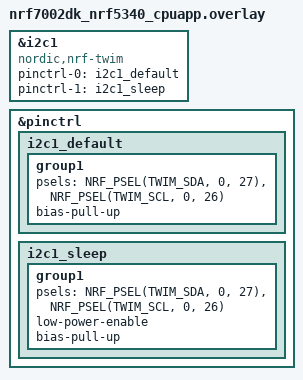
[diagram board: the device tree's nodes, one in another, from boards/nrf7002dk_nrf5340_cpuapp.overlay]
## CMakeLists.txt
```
cmake_minimum_required(VERSION 3.20.0)
find_package(Zephyr REQUIRED HINTS $ENV{ZEPHYR_BASE})
project(i2c_mmc5983ma_test)

target_sources(app PRIVATE src/main.c)
```

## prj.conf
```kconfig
# 基础功能
CONFIG_MAIN_STACK_SIZE=2048
CONFIG_SYSTEM_WORKQUEUE_STACK_SIZE=2048
CONFIG_HEAP_MEM_POOL_SIZE=1024

# I2C 支持
CONFIG_I2C=y

# 打印与日志系统
CONFIG_PRINTK=y
CONFIG_CONSOLE=y
CONFIG_UART_CONSOLE=y
CONFIG_SERIAL=y
CONFIG_LOG=y
CONFIG_LOG_DEFAULT_LEVEL=3
CONFIG_LOG_BACKEND_UART=y
CONFIG_STDOUT_CONSOLE=y


CONFIG_CBPRINTF_FP_SUPPORT=y
CONFIG_LOG=y
```

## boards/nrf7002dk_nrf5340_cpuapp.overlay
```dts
&i2c1 {
    compatible = "nordic,nrf-twim";
    status = "okay";
    pinctrl-0 = <&i2c1_default>;
    pinctrl-1 = <&i2c1_sleep>;
    pinctrl-names = "default", "sleep";
};

&pinctrl {
    i2c1_default: i2c1_default {
        group1 {
            psels = <NRF_PSEL(TWIM_SDA, 0, 27)>,
                    <NRF_PSEL(TWIM_SCL, 0, 26)>;
            bias-pull-up; 

        };
    };

    i2c1_sleep: i2c1_sleep {
        group1 {
            psels = <NRF_PSEL(TWIM_SDA, 0, 27)>,
                    <NRF_PSEL(TWIM_SCL, 0, 26)>;
            low-power-enable;
            bias-pull-up; 

        };
    };
};
```

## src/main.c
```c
#include <zephyr/drivers/i2c.h>
#include <zephyr/kernel.h>
#include <zephyr/logging/log.h>

LOG_MODULE_REGISTER(mmc5983ma, LOG_LEVEL_INF);

#define MMC5983MA_ADDR 0x30

// 寄存器定义
#define MMC5983MA_REG_XOUT0 0x00
#define MMC5983MA_REG_XOUT1 0x01
#define MMC5983MA_REG_YOUT0 0x02
#define MMC5983MA_REG_YOUT1 0x03
#define MMC5983MA_REG_ZOUT0 0x04
#define MMC5983MA_REG_ZOUT1 0x05
#define MMC5983MA_REG_XYZOUT2 0x06
#define MMC5983MA_REG_TOUT 0x07
#define MMC5983MA_REG_STATUS 0x08
#define MMC5983MA_REG_CTRL0 0x09
#define MMC5983MA_REG_CTRL1 0x0A
#define MMC5983MA_REG_CTRL2 0x0B
#define MMC5983MA_REG_PRODUCT_ID 0x2F

// 控制寄存器位定义
#define MMC5983MA_CTRL0_TM 0x01       // 启动单次测量
#define MMC5983MA_CTRL0_SET 0x08      // SET操作
#define MMC5983MA_CTRL0_RESET 0x10    // RESET操作
#define MMC5983MA_CTRL1_BW_100HZ 0x00 // 带宽100Hz
#define MMC5983MA_CTRL2_CMM_EN 0x10   // 连续测量模式

// 初始化传感器
int mmc5983ma_init(const struct device *i2c_dev) {
  uint8_t product_id;
  uint8_t reg = MMC5983MA_REG_PRODUCT_ID;

  // 读取Product ID验证通信
  int ret = i2c_write_read(i2c_dev, MMC5983MA_ADDR, &reg, 1, &product_id, 1);
  if (ret != 0) {
    LOG_ERR("Failed to read Product ID");
    return ret;
  }

  if (product_id != 0x30) {
    LOG_ERR("Invalid Product ID: 0x%02X", product_id);
    return -EIO;
  }

  LOG_INF("MMC5983MA detected, Product ID: 0x%02X", product_id);

  // 执行SET操作（校准）
  uint8_t cmd[2] = {MMC5983MA_REG_CTRL0, MMC5983MA_CTRL0_SET};
  ret = i2c_write(i2c_dev, cmd, 2, MMC5983MA_ADDR);
  if (ret != 0) {
    LOG_ERR("Failed to send SET command");
    return ret;
  }
  k_msleep(1);

  // 配置带宽
  cmd[0] = MMC5983MA_REG_CTRL1;
  cmd[1] = MMC5983MA_CTRL1_BW_100HZ;
  ret = i2c_write(i2c_dev, cmd, 2, MMC5983MA_ADDR);
  if (ret != 0) {
    LOG_ERR("Failed to configure bandwidth");
    return ret;
  }

  LOG_INF("MMC5983MA initialized successfully");
  return 0;
}

// 读取磁场数据
int mmc5983ma_read_mag(const struct device *i2c_dev, int32_t *x, int32_t *y,
                       int32_t *z) {
  uint8_t data[7];
  uint8_t reg = MMC5983MA_REG_XOUT0;

  // 启动单次测量
  uint8_t cmd[2] = {MMC5983MA_REG_CTRL0, MMC5983MA_CTRL0_TM};
  int ret = i2c_write(i2c_dev, cmd, 2, MMC5983MA_ADDR);
  if (ret != 0) {
    return ret;
  }

  // 等待测量完成（约8ms）
  k_msleep(10);

  // 读取7个字节数据（X0, X1, Y0, Y1, Z0, Z1, XYZ2）
  ret = i2c_write_read(i2c_dev, MMC5983MA_ADDR, &reg, 1, data, 7);
  if (ret != 0) {
    return ret;
  }

  // 组合18位数据
  // X = X_OUT[17:0] = {XOUT1[7:0], XOUT0[7:0], XYZOUT2[7:6]}
  *x = ((uint32_t)data[0] << 10) | ((uint32_t)data[1] << 2) |
       ((data[6] >> 6) & 0x03);
  *y = ((uint32_t)data[2] << 10) | ((uint32_t)data[3] << 2) |
       ((data[6] >> 4) & 0x03);
  *z = ((uint32_t)data[4] << 10) | ((uint32_t)data[5] << 2) |
       ((data[6] >> 2) & 0x03);

  // 转换为有符号值（以131072为中心）
  *x -= 131072;
  *y -= 131072;
  *z -= 131072;

  return 0;
}

void main(void) {
  LOG_INF("=== MMC5983MA Magnetometer Test ===");

  const struct device *i2c_dev = DEVICE_DT_GET(DT_NODELABEL(i2c1));
  if (!device_is_ready(i2c_dev)) {
    LOG_ERR("I2C device not ready");
    return;
  }

  // 初始化传感器
  if (mmc5983ma_init(i2c_dev) != 0) {
    LOG_ERR("Failed to initialize MMC5983MA");
    return;
  }

  // 主循环：读取磁场数据
  while (1) {
    int32_t x, y, z;

    if (mmc5983ma_read_mag(i2c_dev, &x, &y, &z) == 0) {
      // 转换为高斯（Gauss）
      // MMC5983MA: 1 LSB = 0.0625 mG = 0.0000625 G
      float x_gauss = x * 0.0000625f;
      float y_gauss = y * 0.0000625f;
      float z_gauss = z * 0.0000625f;

      LOG_INF("Mag [G]: X=%.4f, Y=%.4f, Z=%.4f", (double)x_gauss,
              (double)y_gauss, (double)z_gauss);

      // 计算磁场强度
      float magnitude =
          sqrtf(x_gauss * x_gauss + y_gauss * y_gauss + z_gauss * z_gauss);
      LOG_INF("Magnitude: %.4f G", (double)magnitude);
    } else {
      LOG_ERR("Failed to read magnetometer data");
    }

    k_msleep(1000); // 每秒读取一次
  }
}

// #include <zephyr/drivers/i2c.h>
// #include <zephyr/logging/log.h>
// #include <zephyr/kernel.h>

// LOG_MODULE_REGISTER(i2c_test, LOG_LEVEL_INF);

// #define MMC5983MA_ADDR          0x30
// #define MMC5983MA_REG_PRODUCT_ID 0x2F

// void main(void)
// {
//     printk("=== Booting I2C test ===\n");

//     const struct device *i2c_dev = DEVICE_DT_GET(DT_NODELABEL(i2c1));
//     if (!device_is_ready(i2c_dev)) {
//         LOG_ERR("I2C device not ready");
//         return;
//     }

//     uint8_t reg = MMC5983MA_REG_PRODUCT_ID;
//     uint8_t id = 0;

//     while (1) {
//         int ret = i2c_write_read(i2c_dev, MMC5983MA_ADDR,
//                                  &reg, 1, &id, 1);

//         if (ret == 0) {
//             LOG_INF("MMC5983MA Product ID: 0x%02X", id);
//         } else {
//             LOG_ERR("I2C communication failed, ret=%d", ret);
//         }

//         k_msleep(500);
//     }
// }

// #include <zephyr/drivers/i2c.h>
// #include <zephyr/logging/log.h>
// LOG_MODULE_REGISTER(i2c_test, LOG_LEVEL_INF);

// #define MMC5983MA_ADDR 0x30
// #define MMC5983MA_REG_PRODUCT_ID 0x2F

// void main(void)
// {
// 	printk("=== Booting I2C test ===\n");

//     const struct device *i2c_dev = DEVICE_DT_GET(DT_NODELABEL(i2c1));
//     if (!device_is_ready(i2c_dev)) {
//         LOG_ERR("I2C device not ready");
//         return;
//     }

//     uint8_t reg = MMC5983MA_REG_PRODUCT_ID;
//     uint8_t id = 0;

//     if (i2c_write_read(i2c_dev, MMC5983MA_ADDR, &reg, 1, &id, 1) == 0) {
//         LOG_INF("MMC5983MA Product ID: 0x%02X", id);
//     } else {
//         LOG_ERR("I2C communication failed");
//     }
// }

// #include <zephyr/kernel.h>
// #include <zephyr/drivers/i2c.h>
// #include <zephyr/logging/log.h>

// LOG_MODULE_REGISTER(i2c_scan, LOG_LEVEL_INF);

// void main(void)
// {
//     const struct device *i2c_dev = DEVICE_DT_GET(DT_NODELABEL(i2c1));
//     if (!device_is_ready(i2c_dev)) {
//         printk("I2C1 not ready!\n");
//         return;
//     }

// 	k_msleep(20);

//     printk("=== Scanning I2C Bus ===\n");

//     // for (uint8_t addr = 1; addr < 0x7F; addr++) {
//     //     uint8_t reg = 0;
//     //     if (i2c_write_read(i2c_dev, addr, &reg, 1, NULL, 0) == 0) {
//     //         printk("Found device at 0x%02X\n", addr);
//     //     }
//     //     k_msleep(10);
//     // }

// 	for (uint8_t addr = 1; addr < 0x7F; addr++) {
//     uint8_t reg = 0;
//     int ret = i2c_write_read(i2c_dev, addr, &reg, 1, NULL, 0);
//     if (ret == 0) {
//         printk("✅ Found device at 0x%02X\n", addr);
//     } else {
//         // Uncomment this line to debug
//         printk("Addr 0x%02X no ack (%d)\n", addr, ret);
//     }
//     k_msleep(10);
// }

//     printk("=== Scan Done ===\n");
// }

// #include <zephyr/drivers/i2c.h>
// #include <zephyr/logging/log.h>
// LOG_MODULE_REGISTER(i2c_scan, LOG_LEVEL_INF);

// void main(void)
// {
//     const struct device *i2c_dev = DEVICE_DT_GET(DT_NODELABEL(i2c1));
//     if (!device_is_ready(i2c_dev)) {
//         LOG_ERR("I2C device not ready");
//         return;
//     }

//     LOG_INF("Scanning I2C bus...");
//     for (uint8_t addr = 1; addr < 0x7F; addr++) {
//         uint8_t dummy;
//         int ret = i2c_read(i2c_dev, &dummy, 1, addr);
//         if (ret == 0) {
//             LOG_INF("Found device at address 0x%02X", addr);
//         }
//     }
// }
```

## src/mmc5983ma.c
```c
/*
 * MMC5983MA Magnetometer Driver - Core Functions
 * SPDX-License-Identifier: Apache-2.0
 *
 * These functions contain the testable logic (data conversion, validation)
 * that can run on native_sim without hardware.
 */

#include "mmc5983ma.h"
#include <math.h>

/**
 * @brief Convert raw register bytes to 18-bit signed values
 *
 * The MMC5983MA outputs 18-bit values split across registers:
 * - X: XOUT0[7:0], XOUT1[7:0], XYZOUT2[7:6]
 * - Y: YOUT0[7:0], YOUT1[7:0], XYZOUT2[5:4]
 * - Z: ZOUT0[7:0], ZOUT1[7:0], XYZOUT2[3:2]
 *
 * Raw values are unsigned with offset at 131072 (2^17)
 */
void mmc5983ma_convert_raw_bytes(const uint8_t *raw_bytes,
                                 struct mmc5983ma_raw_data *data) {
  uint32_t x_raw, y_raw, z_raw;

  /* Combine bytes into 18-bit unsigned values */
  /* Byte order: [0]=XOUT0, [1]=XOUT1, [2]=YOUT0, [3]=YOUT1,
   *             [4]=ZOUT0, [5]=ZOUT1, [6]=XYZOUT2 */
  x_raw = ((uint32_t)raw_bytes[0] << 10) | ((uint32_t)raw_bytes[1] << 2) |
          ((raw_bytes[6] >> 6) & 0x03);

  y_raw = ((uint32_t)raw_bytes[2] << 10) | ((uint32_t)raw_bytes[3] << 2) |
          ((raw_bytes[6] >> 4) & 0x03);

  z_raw = ((uint32_t)raw_bytes[4] << 10) | ((uint32_t)raw_bytes[5] << 2) |
          ((raw_bytes[6] >> 2) & 0x03);

  /* Convert to signed by subtracting offset */
  data->x = (int32_t)x_raw - MMC5983MA_OFFSET;
  data->y = (int32_t)y_raw - MMC5983MA_OFFSET;
  data->z = (int32_t)z_raw - MMC5983MA_OFFSET;
}

/**
 * @brief Convert raw counts to Gauss
 *
 * MMC5983MA sensitivity: 1 LSB = 0.0625 mG = 0.0000625 G
 */
void mmc5983ma_convert_to_gauss(const struct mmc5983ma_raw_data *raw,
                                struct mmc5983ma_data *data) {
  data->x = (float)raw->x * MMC5983MA_LSB_TO_GAUSS;
  data->y = (float)raw->y * MMC5983MA_LSB_TO_GAUSS;
  data->z = (float)raw->z * MMC5983MA_LSB_TO_GAUSS;
  data->magnitude = mmc5983ma_calculate_magnitude(data->x, data->y, data->z);
}

/**
 * @brief Validate product ID
 */
int mmc5983ma_validate_product_id(uint8_t product_id) {
  if (product_id == MMC5983MA_PRODUCT_ID) {
    return 0;
  }
  return -1;
}

/**
 * @brief Calculate magnetic field magnitude
 */
float mmc5983ma_calculate_magnitude(float x, float y, float z) {
  return sqrtf(x * x + y * y + z * z);
}
```

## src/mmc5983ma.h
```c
/*
 * MMC5983MA Magnetometer Driver
 * SPDX-License-Identifier: Apache-2.0
 */

#ifndef MMC5983MA_H
#define MMC5983MA_H

#include <stdint.h>

/* MMC5983MA I2C Address */
#define MMC5983MA_ADDR 0x30

/* Register definitions */
#define MMC5983MA_REG_XOUT0 0x00
#define MMC5983MA_REG_XOUT1 0x01
#define MMC5983MA_REG_YOUT0 0x02
#define MMC5983MA_REG_YOUT1 0x03
#define MMC5983MA_REG_ZOUT0 0x04
#define MMC5983MA_REG_ZOUT1 0x05
#define MMC5983MA_REG_XYZOUT2 0x06
#define MMC5983MA_REG_TOUT 0x07
#define MMC5983MA_REG_STATUS 0x08
#define MMC5983MA_REG_CTRL0 0x09
#define MMC5983MA_REG_CTRL1 0x0A
#define MMC5983MA_REG_CTRL2 0x0B
#define MMC5983MA_REG_PRODUCT_ID 0x2F

/* Expected Product ID */
#define MMC5983MA_PRODUCT_ID 0x30

/* Control register bits */
#define MMC5983MA_CTRL0_TM 0x01       /* Trigger measurement */
#define MMC5983MA_CTRL0_SET 0x08      /* SET operation */
#define MMC5983MA_CTRL0_RESET 0x10    /* RESET operation */
#define MMC5983MA_CTRL1_BW_100HZ 0x00 /* Bandwidth 100Hz */
#define MMC5983MA_CTRL2_CMM_EN 0x10   /* Continuous measurement mode */

/* Conversion constants */
#define MMC5983MA_OFFSET 131072           /* 18-bit midpoint (2^17) */
#define MMC5983MA_LSB_TO_GAUSS 0.0000625f /* 1 LSB = 0.0625 mG */

/**
 * @brief Magnetometer data structure (raw counts)
 */
struct mmc5983ma_raw_data {
  int32_t x;
  int32_t y;
  int32_t z;
};

/**
 * @brief Magnetometer data structure (in Gauss)
 */
struct mmc5983ma_data {
  float x;
  float y;
  float z;
  float magnitude;
};

/**
 * @brief Convert raw register bytes to 18-bit signed values
 *
 * @param raw_bytes Array of 7 bytes from registers 0x00-0x06
 * @param data Output structure with signed x, y, z values
 */
void mmc5983ma_convert_raw_bytes(const uint8_t *raw_bytes,
                                 struct mmc5983ma_raw_data *data);

/**
 * @brief Convert raw counts to Gauss
 *
 * @param raw Raw magnetometer data (signed counts)
 * @param data Output structure with values in Gauss
 */
void mmc5983ma_convert_to_gauss(const struct mmc5983ma_raw_data *raw,
                                struct mmc5983ma_data *data);

/**
 * @brief Validate product ID
 *
 * @param product_id Product ID read from sensor
 * @return 0 if valid, -1 if invalid
 */
int mmc5983ma_validate_product_id(uint8_t product_id);

/**
 * @brief Calculate magnetic field magnitude
 *
 * @param x X-axis value in Gauss
 * @param y Y-axis value in Gauss
 * @param z Z-axis value in Gauss
 * @return Magnitude in Gauss
 */
float mmc5983ma_calculate_magnitude(float x, float y, float z);

#endif /* MMC5983MA_H */
```
